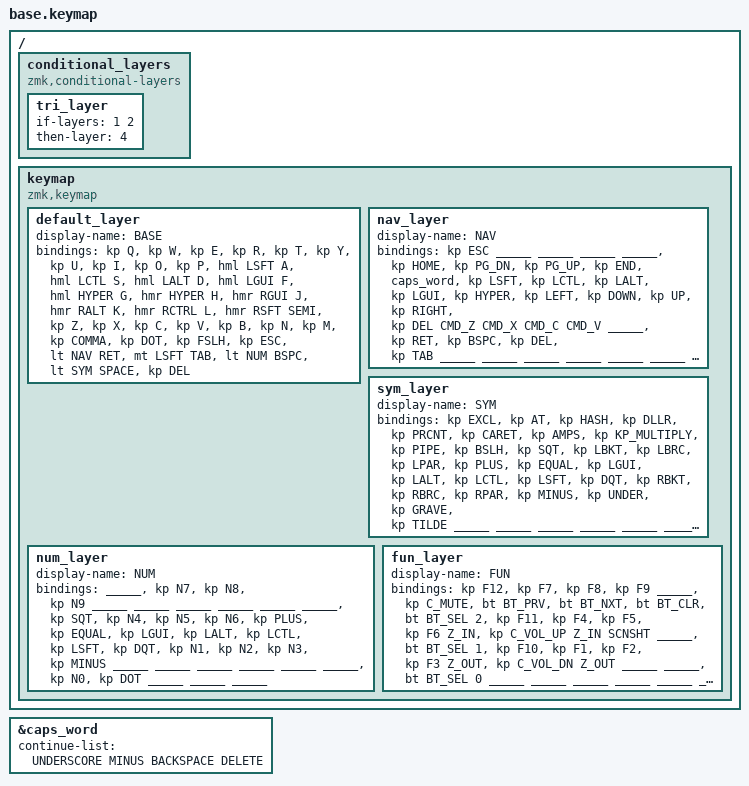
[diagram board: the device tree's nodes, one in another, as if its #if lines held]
#include <behaviors.dtsi>
#include <dt-bindings/zmk/keys.h>
#include <dt-bindings/zmk/bt.h>


/* layers */
#define DEFAULT 0
#define NAV     1 
#define SYM     2 
#define NUM     3 
#define FUN     4 

#include "behaviors.dtsi"
#include "combos.dtsi"

#define XXXXX &none
#define _____ &trans

/* macros */
#define SCNSHT  &kp LC(LS(LG(N4)))
#define Z_IN    &kp LG(EQUAL)
#define Z_OUT   &kp LG(MINUS)
#define CMD_C   &kp LG(C)
#define CMD_V   &kp LG(V)
#define CMD_X   &kp LG(X)
#define CMD_Z   &kp LG(Z)
#define HYPER   LC(LS(LG(LALT)))

/* global config */
&caps_word {
    continue-list = <UNDERSCORE MINUS BACKSPACE DELETE>;
};

/ {
        conditional_layers {
          compatible = "zmk,conditional-layers";
          tri_layer {
            if-layers = <1 2>;
            then-layer = <4>;
          };
        };

        keymap {
                compatible = "zmk,keymap";

                default_layer {
                        display-name = "BASE";
// -------------------------------     --------------------------------
// |  q  |  w  |  f  |  p  |  b  |     |  j  |  l   |  u  |  y  |  '  |
// -------------------------------     --------------------------------
// |  a  |  r  |  s  |  t  |  g  |     |  m  |  n   |  e  |  i  |  o  |
// -------------------------------     --------------------------------
// |  z  |  x  |  c  |  d  |  v  |     |  k  |  h   |  ,  |  .  |  /  |
// -------------------------------     --------------------------------
//             | ESC | RET |SHFT |     | BSPC| SPC  | DEL |
//             -------------------     --------------------
                        bindings = <
   &kp Q        &kp W        &kp E        &kp R        &kp T          &kp Y  &kp U        &kp I          &kp O         &kp P
   &hml LSFT A  &hml LCTL S  &hml LALT D  &hml LGUI F  &hml HYPER G   &hmr HYPER H  &hmr RGUI J  &hmr RALT K    &hmr RCTRL L  &hmr RSFT SEMI 
   &kp Z        &kp X        &kp C        &kp V        &kp B          &kp N  &kp M        &kp COMMA      &kp DOT       &kp FSLH
#ifdef THREE_THUMBS
     &kp ESC &lt NAV RET &mt LSFT TAB    &lt NUM BSPC &lt SYM SPACE &kp DEL
#else
             &lt NAV RET &mt LSFT TAB    &lt NUM BSPC &lt SYM SPACE
#endif
                        >;
                };

                nav_layer {
                        display-name = "NAV";
// -------------------------------      -------------------------------
// | ESC |     |     |     |     |      |HOME |PGDN |PGUP | END | CAP |
// -------------------------------      -------------------------------
// |LSFT |LCTL |LALT |LGUI |HYPER|      |LEFT |DOWN |  UP |RIGHT| DEL |
// -------------------------------      -------------------------------
// |CMD_Z|CMD_X|CMD_C|CMD_V|     |      | ENT |BPSC | TAB |     |     |
// -------------------------------      -------------------------------
//             |     |     |     |      |     |     |     |
//             -------------------      -------------------
                        bindings = <
   &kp ESC   _____     _____     _____    _____       &kp HOME  &kp PG_DN &kp PG_UP &kp END   &caps_word
   &kp LSFT  &kp LCTL  &kp LALT  &kp LGUI &kp HYPER   &kp LEFT  &kp DOWN  &kp UP    &kp RIGHT &kp DEL
   CMD_Z     CMD_X     CMD_C     CMD_V    _____   &kp RET   &kp BSPC  &kp DEL   &kp TAB   _____  
#ifdef THREE_THUMBS
                   	  _____  _____  _____    _____  _____  _____
#else
                   	         _____  _____    _____  _____
#endif
                        >;
                };

                sym_layer {
                        display-name = "SYM";
// -------------------------------     -------------------------------
// |  !  |  @  | '#' |  $  |  %  |     |  ^  |  &  |  *  | '|' |  \  |
// -------------------------------     -------------------------------
// |  :  |  [  |  {  |  (  |  +  |     |  =  |LGUI |LALT |LCTL |LSFT |
// -------------------------------     -------------------------------
// |  ;  |  ]  |  }  |  )  |  -  |     |  _  |  `  |  ~  |     |     |
// -------------------------------     -------------------------------
//             |     |     |     |     |     |     |     |
//             -------------------     -------------------
                        bindings = <
   &kp EXCL &kp AT    &kp HASH  &kp DLLR  &kp PRCNT    &kp CARET &kp AMPS   &kp KP_MULTIPLY  &kp PIPE  &kp BSLH
   &kp SQT  &kp LBKT  &kp LBRC  &kp LPAR  &kp PLUS     &kp EQUAL &kp LGUI   &kp LALT         &kp LCTL  &kp LSFT
   &kp DQT  &kp RBKT  &kp RBRC  &kp RPAR  &kp MINUS    &kp UNDER &kp GRAVE  &kp TILDE        _____     _____
#ifdef THREE_THUMBS
                   	  _____  _____  _____    _____  _____  _____
#else
                   	         _____  _____    _____  _____
#endif
                        >;
                };

                num_layer {
                        display-name = "NUM";
// -------------------------------      -------------------------------
// |     |  7  |  8  |  9  |     |      |     |     |     |     |     |
// -------------------------------      -------------------------------
// |  :  |  4 |   5  |  6  |  +  |      |  =  |LGUI |LALT |LCTL |LSFT |
// -------------------------------      -------------------------------
// |  ;  |  1  |  2  |  3  |  -  |      |     |     |     |     |     |
// -------------------------------      -------------------------------
//             |     |  0  |     |      |     |     |     |
//             -------------------      -------------------
                        bindings = <
   _____     &kp N7  &kp N8  &kp N9  _____       _____     _____     _____     _____     _____ 
   &kp SQT &kp N4  &kp N5  &kp N6  &kp PLUS    &kp EQUAL &kp LGUI  &kp LALT  &kp LCTL  &kp LSFT
   &kp DQT  &kp N1  &kp N2  &kp N3  &kp MINUS   _____     _____     _____     _____     _____
#ifdef THREE_THUMBS
               	  _____  &kp N0  &kp DOT    _____  _____  _____
#else
               	         &kp N0  &kp DOT    _____  _____
#endif
                        >;
                };

                fun_layer {
                        display-name = "FUN";
// -------------------------------      -------------------------------
// | F12 | F7  | F8  | F9  |     |      |MUTE |BT_P |BT_N |BT_CLR|     |
// -------------------------------      -------------------------------
// | F11 | F4  | F5  | F6  |     |      |VOL+ |  Z+ | SCN |     |     |
// -------------------------------      -------------------------------
// | F10 | F1  | F2  | F3  |     |      |VOL- |  Z- |     |     |     |
// -------------------------------      -------------------------------
//             |     |     |     |      |     |     |     |
//             -------------------      -------------------
                        bindings = <
   &kp F12  &kp F7  &kp F8  &kp F9  _____    &kp C_MUTE    &bt BT_PRV  &bt BT_NXT   &bt BT_CLR  &bt BT_SEL 2 
   &kp F11  &kp F4  &kp F5  &kp F6  Z_IN     &kp C_VOL_UP  Z_IN        SCNSHT       _____       &bt BT_SEL 1 
   &kp F10  &kp F1  &kp F2  &kp F3  Z_OUT    &kp C_VOL_DN  Z_OUT       _____        _____  &bt BT_SEL 0
#ifdef THREE_THUMBS
                   	  _____  _____  _____   _____  _____  _____
#else
                   	         _____  _____   _____  _____
#endif
                        >;
                };

        };
};
